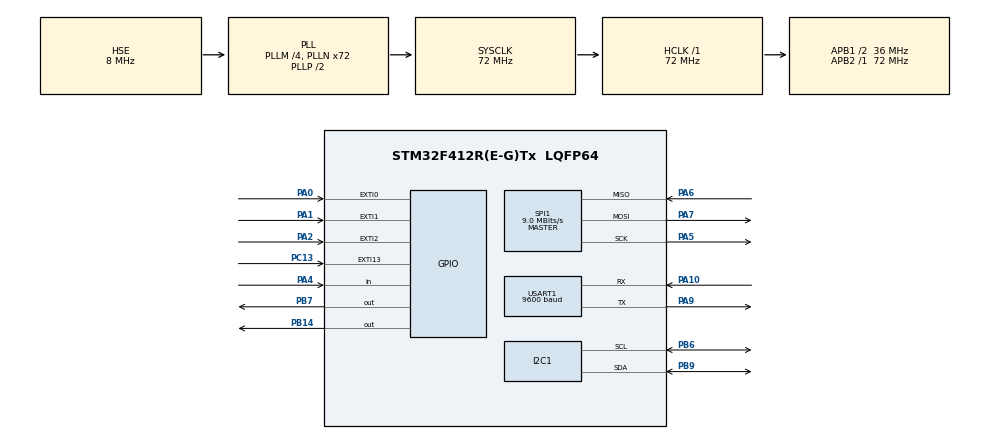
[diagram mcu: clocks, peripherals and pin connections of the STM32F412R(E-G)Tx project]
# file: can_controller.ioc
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Dma.Request0=USART1_RX
Dma.USART1_RX.0.Direction=DMA_PERIPH_TO_MEMORY
Dma.USART1_RX.0.FIFOMode=DMA_FIFOMODE_DISABLE
Dma.USART1_RX.0.Instance=DMA2_Stream2
Dma.USART1_RX.0.MemDataAlignment=DMA_MDATAALIGN_BYTE
Dma.USART1_RX.0.MemInc=DMA_MINC_ENABLE
Dma.USART1_RX.0.Mode=DMA_CIRCULAR
Dma.USART1_RX.0.PeriphDataAlignment=DMA_PDATAALIGN_BYTE
Dma.USART1_RX.0.PeriphInc=DMA_PINC_DISABLE
Dma.USART1_RX.0.Priority=DMA_PRIORITY_HIGH
FATFS._FS_TINY=1
FATFS._USE_LFN=2
FREERTOS.INCLUDE_eTaskGetState=1
FREERTOS.INCLUDE_uxTaskGetStackHighWaterMark=1
FREERTOS.INCLUDE_uxTaskPriorityGet=1
FREERTOS.INCLUDE_vTaskDelay=1
FREERTOS.INCLUDE_vTaskDelayUntil=1
FREERTOS.INCLUDE_vTaskDelete=1
FREERTOS.INCLUDE_vTaskPrioritySet=1
FREERTOS.INCLUDE_vTaskSuspend=1
FREERTOS.INCLUDE_xQueueGetMutexHolder=1
FREERTOS.INCLUDE_xSemaphoreGetMutexHolder=1
FREERTOS.INCLUDE_xTaskGetSchedulerState=1
FREERTOS.INCLUDE_xTimerPendFunctionCall=1
FREERTOS.Queues01=controllerQueue,20,uint32_t,0,Static,controllerQueueBuffer,controllerQueueBLock
FREERTOS.Tasks01=controller_thre,24,512,controller_thread_handle,As weak,NULL,Dynamic,NULL,NULL;can_thread_hand,24,900,can_thread_handler,As weak,NULL,Dynamic,NULL,NULL
FREERTOS.configGENERATE_RUN_TIME_STATS=1
FREERTOS.configRECORD_STACK_HIGH_ADDRESS=1
I2C1.I2C_Mode=I2C_Fast
Mcu.Family=STM32F4
Mcu.Name=STM32F412R(E-G)Tx
Mcu.Package=LQFP64
NVIC.DMA2_Stream2_IRQn=true\:5\:0\:false\:false\:true\:true\:false\:true\:true
NVIC.EXTI0_IRQn=true\:5\:0\:false\:false\:true\:true\:true\:true\:true
NVIC.EXTI15_10_IRQn=true\:5\:0\:false\:false\:true\:true\:true\:true\:true
NVIC.EXTI1_IRQn=true\:5\:0\:false\:false\:true\:true\:true\:true\:true
NVIC.EXTI2_IRQn=true\:5\:0\:false\:false\:true\:true\:true\:true\:true
NVIC.I2C1_ER_IRQn=true\:5\:0\:false\:false\:true\:true\:true\:true\:true
NVIC.I2C1_EV_IRQn=true\:5\:0\:false\:false\:true\:true\:true\:true\:true
NVIC.PriorityGroup=NVIC_PRIORITYGROUP_4
NVIC.SPI1_IRQn=true\:5\:0\:false\:false\:true\:true\:true\:true\:true
NVIC.TIM1_UP_TIM10_IRQn=true\:15\:0\:false\:false\:true\:false\:false\:true\:true
NVIC.TIM6_IRQn=true\:5\:0\:false\:false\:true\:true\:true\:true\:true
NVIC.TimeBase=TIM1_UP_TIM10_IRQn
NVIC.TimeBaseIP=TIM1
NVIC.USART1_IRQn=true\:5\:0\:false\:false\:true\:true\:true\:true\:true
PA0.GPIO_ModeDefaultEXTI=GPIO_MODE_IT_RISING
PA0.GPIO_PuPd=GPIO_NOPULL
PA0.Signal=GPXTI0
PA1.GPIO_ModeDefaultEXTI=GPIO_MODE_IT_RISING
PA1.GPIO_PuPd=GPIO_NOPULL
PA1.Signal=GPXTI1
PA10.Mode=Asynchronous
PA10.Signal=USART1_RX
PA13.Mode=Trace_Asynchronous_SW
PA13.Signal=SYS_JTMS-SWDIO
PA14.Mode=Trace_Asynchronous_SW
PA14.Signal=SYS_JTCK-SWCLK
PA2.GPIO_ModeDefaultEXTI=GPIO_MODE_IT_RISING
PA2.GPIO_PuPd=GPIO_NOPULL
PA2.Signal=GPXTI2
PA4.GPIO_PuPd=GPIO_PULLUP
PA4.Signal=GPIO_Input
PA5.Mode=Full_Duplex_Master
PA5.Signal=SPI1_SCK
PA6.Mode=Full_Duplex_Master
PA6.Signal=SPI1_MISO
PA7.Mode=Full_Duplex_Master
PA7.Signal=SPI1_MOSI
PA9.Mode=Asynchronous
PA9.Signal=USART1_TX
PB14.Signal=GPIO_Output
PB3.Mode=Trace_Asynchronous_SW
PB3.Signal=SYS_JTDO-SWO
PB6.GPIO_Pu=GPIO_PULLUP
PB6.Mode=I2C
PB6.Signal=I2C1_SCL
PB7.Signal=GPIO_Output
PB9.GPIO_Pu=GPIO_PULLUP
PB9.Mode=I2C
PB9.Signal=I2C1_SDA
PC13.GPIO_ModeDefaultEXTI=GPIO_MODE_IT_RISING
PC13.GPIO_PuPd=GPIO_NOPULL
PC13.Signal=GPXTI13
PC14-OSC32_IN.Mode=LSE-External-Oscillator
PC14-OSC32_IN.Signal=RCC_OSC32_IN
PC15-OSC32_OUT.Mode=LSE-External-Oscillator
PC15-OSC32_OUT.Signal=RCC_OSC32_OUT
PH0\ -\ OSC_IN.Mode=HSE-External-Oscillator
PH0\ -\ OSC_IN.Signal=RCC_OSC_IN
PH1\ -\ OSC_OUT.Mode=HSE-External-Oscillator
PH1\ -\ OSC_OUT.Signal=RCC_OSC_OUT
ProjectManager.HeapSize=0x200
ProjectManager.StackSize=0x400
ProjectManager.TargetToolchain=CMake
RCC.AHBFreq_Value=72000000
RCC.APB1CLKDivider=RCC_HCLK_DIV2
RCC.APB1Freq_Value=36000000
RCC.APB1TimFreq_Value=72000000
RCC.APB2Freq_Value=72000000
RCC.APB2TimFreq_Value=72000000
RCC.CortexFreq_Value=72000000
RCC.HCLKFreq_Value=72000000
RCC.HSE_VALUE=8000000
RCC.PLLM=4
RCC.PLLN=72
RCC.PLLQ=3
RCC.PLLSourceVirtual=RCC_PLLSOURCE_HSE
RCC.RCC_RTC_Clock_Source=RCC_RTCCLKSOURCE_LSE
RCC.RCC_RTC_Clock_SourceVirtual=RCC_RTCCLKSOURCE_LSE
RCC.SYSCLKFreq_VALUE=72000000
RCC.SYSCLKSource=RCC_SYSCLKSOURCE_PLLCLK
RCC.USBFreq_Value=48000000
RCC.VCOOutputFreq_Value=144000000
SPI1.BaudRatePrescaler=SPI_BAUDRATEPRESCALER_8
SPI1.CalculateBaudRate=9.0 MBits/s
SPI1.Direction=SPI_DIRECTION_2LINES
SPI1.Mode=SPI_MODE_MASTER
SPI1.VirtualType=VM_MASTER
TIM6.Period=35156-1
TIM6.Prescaler=2048
USART1.BaudRate=9600
USART1.VirtualMode=VM_ASYNC
VP_FATFS_VS_Generic.Mode=User_defined
VP_FREERTOS_VS_CMSIS_V2.Mode=CMSIS_V2
VP_RTC_VS_RTC_Activate.Mode=RTC_Enabled
VP_SYS_VS_tim1.Mode=TIM1
VP_TIM6_VS_ClockSourceINT.Mode=Enable_Timer
VP_TIM6_VS_OPM.Mode=OPM_bit
board=custom

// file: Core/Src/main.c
/* USER CODE BEGIN Header */
/**
  ******************************************************************************
  * @file           : main.c
  * @brief          : Main program body
  ******************************************************************************
  * @attention
  *
  * Copyright (c) 2025 STMicroelectronics.
  * All rights reserved.
  *
  * This software is licensed under terms that can be found in the LICENSE file
  * in the root directory of this software component.
  * If no LICENSE file comes with this software, it is provided AS-IS.
  *
  ******************************************************************************
  */
/* USER CODE END Header */
#include "main.h"
#include "cmsis_os.h"
#include "dma.h"
#include "fatfs.h"
#include "i2c.h"
#include "rtc.h"
#include "spi.h"
#include "tim.h"
#include "usart.h"
#include "gpio.h"

/* USER CODE BEGIN Includes */
#include "ssd1306.h"
#include "ssd1306_fonts.h"
#include "can.h"
/* USER CODE END Includes */

void SystemClock_Config(void);
void MX_FREERTOS_Init(void);

int main(void)
{

  /* MCU Configuration--------------------------------------------------------*/

  /* Reset of all peripherals, Initializes the Flash interface and the Systick. */
  HAL_Init();

  /* Configure the system clock */
  SystemClock_Config();

  /* Initialize all configured peripherals */
  MX_GPIO_Init();
  MX_DMA_Init();
  MX_I2C1_Init();
  MX_RTC_Init();
  MX_USART1_UART_Init();
  MX_SPI1_Init();
  MX_FATFS_Init();
  MX_TIM6_Init();

  /* Init scheduler */
  osKernelInitialize();  /* Call init function for freertos objects (in cmsis_os2.c) */
  MX_FREERTOS_Init();

  /* Start scheduler */
  osKernelStart();

  /* We should never get here as control is now taken by the scheduler */

  /* Infinite loop */
  while (1)
  {

  }
}

void SystemClock_Config(void)
{
  RCC_OscInitTypeDef RCC_OscInitStruct = {0};
  RCC_ClkInitTypeDef RCC_ClkInitStruct = {0};

  /** Configure the main internal regulator output voltage
  */
  __HAL_RCC_PWR_CLK_ENABLE();
  __HAL_PWR_VOLTAGESCALING_CONFIG(PWR_REGULATOR_VOLTAGE_SCALE1);

  /** Initializes the RCC Oscillators according to the specified parameters
  * in the RCC_OscInitTypeDef structure.
  */
  RCC_OscInitStruct.OscillatorType = RCC_OSCILLATORTYPE_HSE|RCC_OSCILLATORTYPE_LSE;
  RCC_OscInitStruct.HSEState = RCC_HSE_ON;
  RCC_OscInitStruct.LSEState = RCC_LSE_ON;
  RCC_OscInitStruct.PLL.PLLState = RCC_PLL_ON;
  RCC_OscInitStruct.PLL.PLLSource = RCC_PLLSOURCE_HSE;
  RCC_OscInitStruct.PLL.PLLM = 4;
  RCC_OscInitStruct.PLL.PLLN = 72;
  RCC_OscInitStruct.PLL.PLLP = RCC_PLLP_DIV2;
  RCC_OscInitStruct.PLL.PLLQ = 3;
  RCC_OscInitStruct.PLL.PLLR = 2;
  if (HAL_RCC_OscConfig(&RCC_OscInitStruct) != HAL_OK)
  {
    Error_Handler();
  }

  /** Initializes the CPU, AHB and APB buses clocks
  */
  RCC_ClkInitStruct.ClockType = RCC_CLOCKTYPE_HCLK|RCC_CLOCKTYPE_SYSCLK
                              |RCC_CLOCKTYPE_PCLK1|RCC_CLOCKTYPE_PCLK2;
  RCC_ClkInitStruct.SYSCLKSource = RCC_SYSCLKSOURCE_PLLCLK;
  RCC_ClkInitStruct.AHBCLKDivider = RCC_SYSCLK_DIV1;
  RCC_ClkInitStruct.APB1CLKDivider = RCC_HCLK_DIV2;
  RCC_ClkInitStruct.APB2CLKDivider = RCC_HCLK_DIV1;

  if (HAL_RCC_ClockConfig(&RCC_ClkInitStruct, FLASH_LATENCY_2) != HAL_OK)
  {
    Error_Handler();
  }
}

void HAL_TIM_PeriodElapsedCallback(TIM_HandleTypeDef *htim)
{
  if (htim->Instance == TIM1)
  {
    HAL_IncTick();
  }
  /* USER CODE BEGIN Callback 1 */
  if ( TIM6 == htim->Instance ) {
    dt_transmit();
  }
  /* USER CODE END Callback 1 */
}

void Error_Handler(void)
{
  /* USER CODE BEGIN Error_Handler_Debug */
  /* User can add his own implementation to report the HAL error return state */
  // Set an error pin to indicate an error state
  // This can be used for debugging purposes or to indicate an error state
  GPIO_InitTypeDef GPIO_InitStruct = {0};
  GPIO_InitStruct.Pin = GPIO_PIN_14;
  GPIO_InitStruct.Mode = GPIO_MODE_OUTPUT_PP;
  GPIO_InitStruct.Pull = GPIO_NOPULL;
  HAL_GPIO_Init(GPIOB, &GPIO_InitStruct);
  HAL_GPIO_WritePin(GPIOB, GPIO_PIN_14, GPIO_PIN_SET);
  __disable_irq();
  while (1)
  {
  }
  /* USER CODE END Error_Handler_Debug */
}

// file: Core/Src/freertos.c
/* USER CODE BEGIN Header */
/**
  ******************************************************************************
  * File Name          : freertos.c
  * Description        : Code for freertos applications
  ******************************************************************************
  * @attention
  *
  * Copyright (c) 2025 STMicroelectronics.
  * All rights reserved.
  *
  * This software is licensed under terms that can be found in the LICENSE file
  * in the root directory of this software component.
  * If no LICENSE file comes with this software, it is provided AS-IS.
  *
  ******************************************************************************
  */
/* USER CODE END Header */

#include "FreeRTOS.h"
#include "task.h"
#include "main.h"
#include "cmsis_os.h"

/* USER CODE BEGIN Includes */
#include <stdio.h>

/* USER CODE END Includes */

typedef StaticQueue_t osStaticMessageQDef_t;

/* Definitions for controller_thre */
osThreadId_t controller_threHandle;
const osThreadAttr_t controller_thre_attributes = {
  .name = "controller_thre",
  .stack_size = 512 * 4,
  .priority = (osPriority_t) osPriorityNormal,
};
/* Definitions for can_thread_hand */
osThreadId_t can_thread_handHandle;
const osThreadAttr_t can_thread_hand_attributes = {
  .name = "can_thread_hand",
  .stack_size = 900 * 4,
  .priority = (osPriority_t) osPriorityNormal,
};
/* Definitions for controllerQueue */
osMessageQueueId_t controllerQueueHandle;
uint8_t controllerQueueBuffer[ 20 * sizeof( uint32_t ) ];
osStaticMessageQDef_t controllerQueueBLock;
const osMessageQueueAttr_t controllerQueue_attributes = {
  .name = "controllerQueue",
  .cb_mem = &controllerQueueBLock,
  .cb_size = sizeof(controllerQueueBLock),
  .mq_mem = &controllerQueueBuffer,
  .mq_size = sizeof(controllerQueueBuffer)
};

void controller_thread_handle(void *argument);
void can_thread_handler(void *argument);

void MX_FREERTOS_Init(void); /* (MISRA C 2004 rule 8.1) */

/* Hook prototypes */
void configureTimerForRunTimeStats(void);
unsigned long getRunTimeCounterValue(void);

/* USER CODE BEGIN 1 */
/* Functions needed when configGENERATE_RUN_TIME_STATS is on */
__weak void configureTimerForRunTimeStats(void)
{

}

__weak unsigned long getRunTimeCounterValue(void)
{
return 0;
}
/* USER CODE END 1 */

void MX_FREERTOS_Init(void) {

  /* Create the queue(s) */
  /* creation of controllerQueue */
  controllerQueueHandle = osMessageQueueNew (20, sizeof(uint32_t), &controllerQueue_attributes);

  /* Create the thread(s) */
  /* creation of controller_thre */
  controller_threHandle = osThreadNew(controller_thread_handle, NULL, &controller_thre_attributes);

  /* creation of can_thread_hand */
  can_thread_handHandle = osThreadNew(can_thread_handler, NULL, &can_thread_hand_attributes);

}

__weak void controller_thread_handle(void *argument)
{
  /* USER CODE BEGIN controller_thread_handle */
  UNUSED(argument);

  /* Infinite loop */
  for(;;)
  {
    osDelay(1);
  }
  /* USER CODE END controller_thread_handle */
}

__weak void can_thread_handler(void *argument)
{
  /* USER CODE BEGIN can_thread_handler */
  UNUSED(argument);

  /* Infinite loop */
  for(;;)
  {
    osDelay(1);
  }
  /* USER CODE END can_thread_handler */
}
